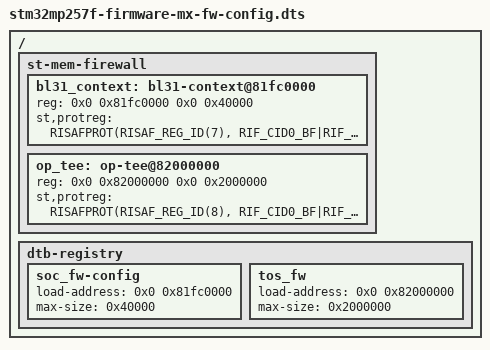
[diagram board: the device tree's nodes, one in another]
// SPDX-License-Identifier: (GPL-2.0-only OR BSD-3-Clause)
/*
 * Copyright (C) 2026, STMicroelectronics - All Rights Reserved
 * Author: STM32CubeMX code generation for STMicroelectronics.
 */

/* For more information on Device Tree configuration, please refer to
 * https://wiki.st.com/stm32mpu/wiki/Category:Device_tree_configuration
 */
#include "stm32mp25-fw-config.dtsi"

/ {
	st-mem-firewall {
		bl31_context: bl31-context@81fc0000 {
			reg = <0x0 0x81fc0000 0x0 0x40000>;
			st,protreg = <RISAFPROT(RISAF_REG_ID(7), RIF_CID0_BF|RIF_CID1_BF|RIF_CID2_BF|RIF_CID3_BF|RIF_CID4_BF|RIF_CID5_BF|RIF_CID6_BF, RIF_CID0_BF|RIF_CID1_BF|RIF_CID2_BF|RIF_CID3_BF|RIF_CID4_BF|RIF_CID5_BF|RIF_CID6_BF, RIF_CID0_BF|RIF_CID1_BF|RIF_CID2_BF|RIF_CID3_BF|RIF_CID4_BF|RIF_CID5_BF|RIF_CID6_BF, RIF_NSEC, RIF_ENC_DIS, RIF_BREN_EN)>;
		};
		op_tee: op-tee@82000000 {
			reg = <0x0 0x82000000 0x0 0x2000000>;
			st,protreg = <RISAFPROT(RISAF_REG_ID(8), RIF_CID0_BF|RIF_CID1_BF|RIF_CID2_BF|RIF_CID3_BF|RIF_CID4_BF|RIF_CID5_BF|RIF_CID6_BF, RIF_CID0_BF|RIF_CID1_BF|RIF_CID2_BF|RIF_CID3_BF|RIF_CID4_BF|RIF_CID5_BF|RIF_CID6_BF, RIF_CID0_BF|RIF_CID1_BF|RIF_CID2_BF|RIF_CID3_BF|RIF_CID4_BF|RIF_CID5_BF|RIF_CID6_BF, RIF_NSEC, RIF_ENC_DIS, RIF_BREN_EN)>;
		};
	};
	/* USER CODE BEGIN root */
	dtb-registry {
		soc_fw-config {
			load-address = <0x0 0x81fc0000>;
			max-size = <0x40000>;
		};
		tos_fw {
			load-address = <0x0 0x82000000>;
			max-size = <0x2000000>;
		};
	};
	/* USER CODE END root */
};
